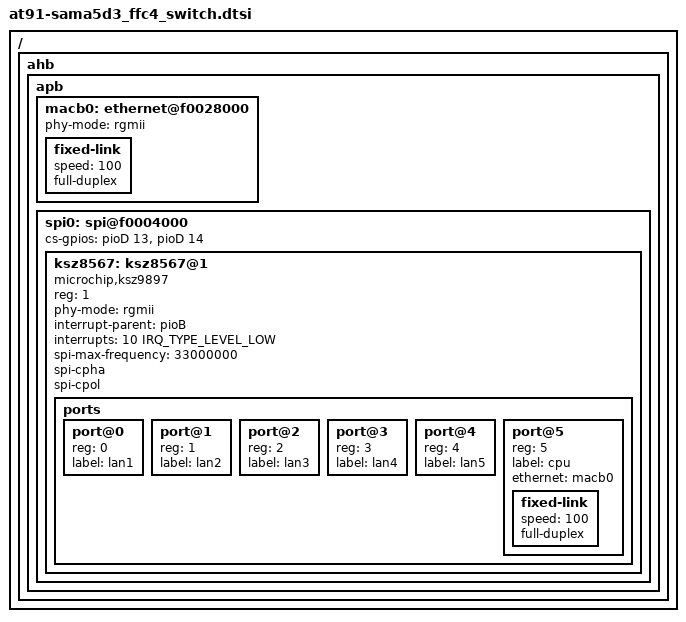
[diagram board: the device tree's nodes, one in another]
/*
 * Device Tree Include file for FFC4 display module on SAMA5D3 FFC4 board
 *
 *  Copyright (C) 2014 Atmel,
 *                2019 Landis+Gyr
 *
 * Licensed under GPLv2.
 */

 
 /{
 	ahb {
		apb {
			macb0: ethernet@f0028000 {
				#address-cells = <1>;
				#size-cells = <0>;
				phy-mode = "rgmii";
				status = "okay";
			
				fixed-link {
					speed = <100>;
					full-duplex;
				};
			};		
			
			spi0: spi@f0004000 {
				cs-gpios = <&pioD 13 0>, <&pioD 14 0>;
				status = "okay";
				ksz8567: ksz8567@1 {
					compatible = "microchip,ksz9897";
					reg = <1>;
					phy-mode = "rgmii";
					interrupt-parent = <&pioB>;
					interrupts = <10 IRQ_TYPE_LEVEL_LOW>;
						
					spi-max-frequency = <33000000>;
					spi-cpha;
					spi-cpol;
					status = "okay";
					
					ports {
						#address-cells = <1>;
						#size-cells = <0>;
						port@0 {
							reg = <0>;
							label = "lan1";
						};
						port@1 {
							reg = <1>;
							label = "lan2";
						};
						port@2 {
							reg = <2>;
							label = "lan3";
						};
						port@3 {
							reg = <3>;
							label = "lan4";
						};
						port@4 {
							reg = <4>;
							label = "lan5";
						};
						port@5 {
							reg = <5>;
							label = "cpu";
							ethernet = <&macb0>;
							fixed-link {
								speed = <100>;
								full-duplex;
							};
						};
					};
				};
			};
		}; 
 	};
 };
